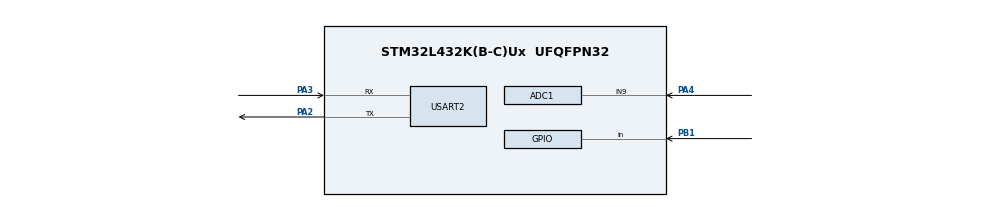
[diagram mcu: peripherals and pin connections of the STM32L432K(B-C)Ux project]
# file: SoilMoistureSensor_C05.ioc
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ADC1.Channel-1\#ChannelRegularConversion=ADC_CHANNEL_9
ADC1.NbrOfConversionFlag=1
ADC1.OffsetNumber-1\#ChannelRegularConversion=ADC_OFFSET_NONE
ADC1.Rank-1\#ChannelRegularConversion=1
ADC1.SamplingTime-1\#ChannelRegularConversion=ADC_SAMPLETIME_2CYCLES_5
ADC1.master=1
Mcu.Family=STM32L4
Mcu.Name=STM32L432K(B-C)Ux
Mcu.Package=UFQFPN32
NVIC.PriorityGroup=NVIC_PRIORITYGROUP_4
PA2.Mode=Asynchronous
PA2.Signal=USART2_TX
PA3.Mode=Asynchronous
PA3.Signal=USART2_RX
PA4.Signal=ADCx_IN9
PB1.Signal=GPIO_Input
ProjectManager.HeapSize=0x200
ProjectManager.StackSize=0x400
ProjectManager.TargetToolchain=STM32CubeIDE
RCC.ADCFreq_Value=32000000
RCC.HSE_VALUE=8000000
RCC.HSI48_VALUE=48000000
RCC.HSI_VALUE=16000000
RCC.LSE_VALUE=32768
RCC.MSI_VALUE=4000000
RCC.PLLSAI1N=16
RCC.USBFreq_Value=32000000
RCC.VCOOutputFreq_Value=32000000
SH.ADCx_IN9.0=ADC1_IN9,IN9-Single-Ended
USART2.VirtualMode-Asynchronous=VM_ASYNC
board=custom

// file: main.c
/* USER CODE BEGIN Header */
/**
  ******************************************************************************
  * @file           : main.c
  * @brief          : This is the main program body for the TRC3500 Team C05.
  *					  All code was part of the pre-built template. Our code
  *					  includes 2 lines in the "Includes" section and all code
  *					  in the "Infinite loop" section.
  ******************************************************************************
  * @attention
  *
  * Copyright (c) 2025 STMicroelectronics.
  * All rights reserved.
  *
  * This software is licensed under terms that can be found in the LICENSE file
  * in the root directory of this software component.
  * If no LICENSE file comes with this software, it is provided AS-IS.
  *
  ******************************************************************************
  */
/* USER CODE END Header */
#include "main.h"

/* USER CODE BEGIN Includes */
#include <stdio.h>
#include <string.h>
/* USER CODE END Includes */

ADC_HandleTypeDef hadc1;

UART_HandleTypeDef huart2;

void SystemClock_Config(void);
static void MX_GPIO_Init(void);
static void MX_ADC1_Init(void);
static void MX_USART2_UART_Init(void);

int main(void)
{

  /* MCU Configuration--------------------------------------------------------*/

  /* Reset of all peripherals, Initializes the Flash interface and the Systick. */
  HAL_Init();

  /* Configure the system clock */
  SystemClock_Config();

  /* Initialize all configured peripherals */
  MX_GPIO_Init();
  MX_ADC1_Init();
  MX_USART2_UART_Init();

  /* Infinite loop */
  /* USER CODE BEGIN WHILE */
  while (1)
  {
	/* Obtain the ADC data and convert it */

	// Initialize the conversion process for ADC
	HAL_ADC_Start(&hadc1);
	// Allow the conversion to take place for as long as it takes
	HAL_ADC_PollForConversion(&hadc1, HAL_MAX_DELAY);
	// Store the 12-bit ADC value (will be between 0 and 4095)
	// The resolution is 2^12, which is  4096 levels
	uint32_t adcValue = HAL_ADC_GetValue(&hadc1);

	/* Print the converted message */

	// Create character arrays to hold the display messages
	char adcMessage[20];
	// Store the message with the raw ADC data for UART
	sprintf(adcMessage, "%lu\r\n", adcValue);
	// Send the message to UART2 for printing via the serial connection
	HAL_UART_Transmit(&huart2, (uint8_t*)adcMessage, strlen(adcMessage), HAL_MAX_DELAY);

	/* Introduce a delay */

	// Delay subsequent messages by 1 second
	HAL_Delay(1000);

    /* USER CODE END WHILE */

  }
}

void SystemClock_Config(void)
{
  RCC_OscInitTypeDef RCC_OscInitStruct = {0};
  RCC_ClkInitTypeDef RCC_ClkInitStruct = {0};

  /** Configure the main internal regulator output voltage
  */
  if (HAL_PWREx_ControlVoltageScaling(PWR_REGULATOR_VOLTAGE_SCALE1) != HAL_OK)
  {
    Error_Handler();
  }

  /** Initializes the RCC Oscillators according to the specified parameters
  * in the RCC_OscInitTypeDef structure.
  */
  RCC_OscInitStruct.OscillatorType = RCC_OSCILLATORTYPE_MSI;
  RCC_OscInitStruct.MSIState = RCC_MSI_ON;
  RCC_OscInitStruct.MSICalibrationValue = 0;
  RCC_OscInitStruct.MSIClockRange = RCC_MSIRANGE_6;
  RCC_OscInitStruct.PLL.PLLState = RCC_PLL_NONE;
  if (HAL_RCC_OscConfig(&RCC_OscInitStruct) != HAL_OK)
  {
    Error_Handler();
  }

  /** Initializes the CPU, AHB and APB buses clocks
  */
  RCC_ClkInitStruct.ClockType = RCC_CLOCKTYPE_HCLK|RCC_CLOCKTYPE_SYSCLK
                              |RCC_CLOCKTYPE_PCLK1|RCC_CLOCKTYPE_PCLK2;
  RCC_ClkInitStruct.SYSCLKSource = RCC_SYSCLKSOURCE_MSI;
  RCC_ClkInitStruct.AHBCLKDivider = RCC_SYSCLK_DIV1;
  RCC_ClkInitStruct.APB1CLKDivider = RCC_HCLK_DIV1;
  RCC_ClkInitStruct.APB2CLKDivider = RCC_HCLK_DIV1;

  if (HAL_RCC_ClockConfig(&RCC_ClkInitStruct, FLASH_LATENCY_0) != HAL_OK)
  {
    Error_Handler();
  }
}

static void MX_ADC1_Init(void)
{

  ADC_ChannelConfTypeDef sConfig = {0};

  /** Common config
  */
  hadc1.Instance = ADC1;
  hadc1.Init.ClockPrescaler = ADC_CLOCK_ASYNC_DIV1;
  hadc1.Init.Resolution = ADC_RESOLUTION_12B;
  hadc1.Init.DataAlign = ADC_DATAALIGN_RIGHT;
  hadc1.Init.ScanConvMode = ADC_SCAN_DISABLE;
  hadc1.Init.EOCSelection = ADC_EOC_SINGLE_CONV;
  hadc1.Init.LowPowerAutoWait = DISABLE;
  hadc1.Init.ContinuousConvMode = DISABLE;
  hadc1.Init.NbrOfConversion = 1;
  hadc1.Init.DiscontinuousConvMode = DISABLE;
  hadc1.Init.ExternalTrigConv = ADC_SOFTWARE_START;
  hadc1.Init.ExternalTrigConvEdge = ADC_EXTERNALTRIGCONVEDGE_NONE;
  hadc1.Init.DMAContinuousRequests = DISABLE;
  hadc1.Init.Overrun = ADC_OVR_DATA_PRESERVED;
  hadc1.Init.OversamplingMode = DISABLE;
  if (HAL_ADC_Init(&hadc1) != HAL_OK)
  {
    Error_Handler();
  }

  /** Configure Regular Channel
  */
  sConfig.Channel = ADC_CHANNEL_9;
  sConfig.Rank = ADC_REGULAR_RANK_1;
  sConfig.SamplingTime = ADC_SAMPLETIME_2CYCLES_5;
  sConfig.SingleDiff = ADC_SINGLE_ENDED;
  sConfig.OffsetNumber = ADC_OFFSET_NONE;
  sConfig.Offset = 0;
  if (HAL_ADC_ConfigChannel(&hadc1, &sConfig) != HAL_OK)
  {
    Error_Handler();
  }

}

static void MX_USART2_UART_Init(void)
{

  huart2.Instance = USART2;
  huart2.Init.BaudRate = 115200;
  huart2.Init.WordLength = UART_WORDLENGTH_8B;
  huart2.Init.StopBits = UART_STOPBITS_1;
  huart2.Init.Parity = UART_PARITY_NONE;
  huart2.Init.Mode = UART_MODE_TX_RX;
  huart2.Init.HwFlowCtl = UART_HWCONTROL_NONE;
  huart2.Init.OverSampling = UART_OVERSAMPLING_16;
  huart2.Init.OneBitSampling = UART_ONE_BIT_SAMPLE_DISABLE;
  huart2.AdvancedInit.AdvFeatureInit = UART_ADVFEATURE_NO_INIT;
  if (HAL_UART_Init(&huart2) != HAL_OK)
  {
    Error_Handler();
  }

}

static void MX_GPIO_Init(void)
{
  GPIO_InitTypeDef GPIO_InitStruct = {0};

  /* GPIO Ports Clock Enable */
  __HAL_RCC_GPIOA_CLK_ENABLE();
  __HAL_RCC_GPIOB_CLK_ENABLE();

  /*Configure GPIO pin : PB1 */
  GPIO_InitStruct.Pin = GPIO_PIN_1;
  GPIO_InitStruct.Mode = GPIO_MODE_INPUT;
  GPIO_InitStruct.Pull = GPIO_NOPULL;
  HAL_GPIO_Init(GPIOB, &GPIO_InitStruct);

}

void Error_Handler(void)
{
  __disable_irq();
  while (1)
  {
  }
}
